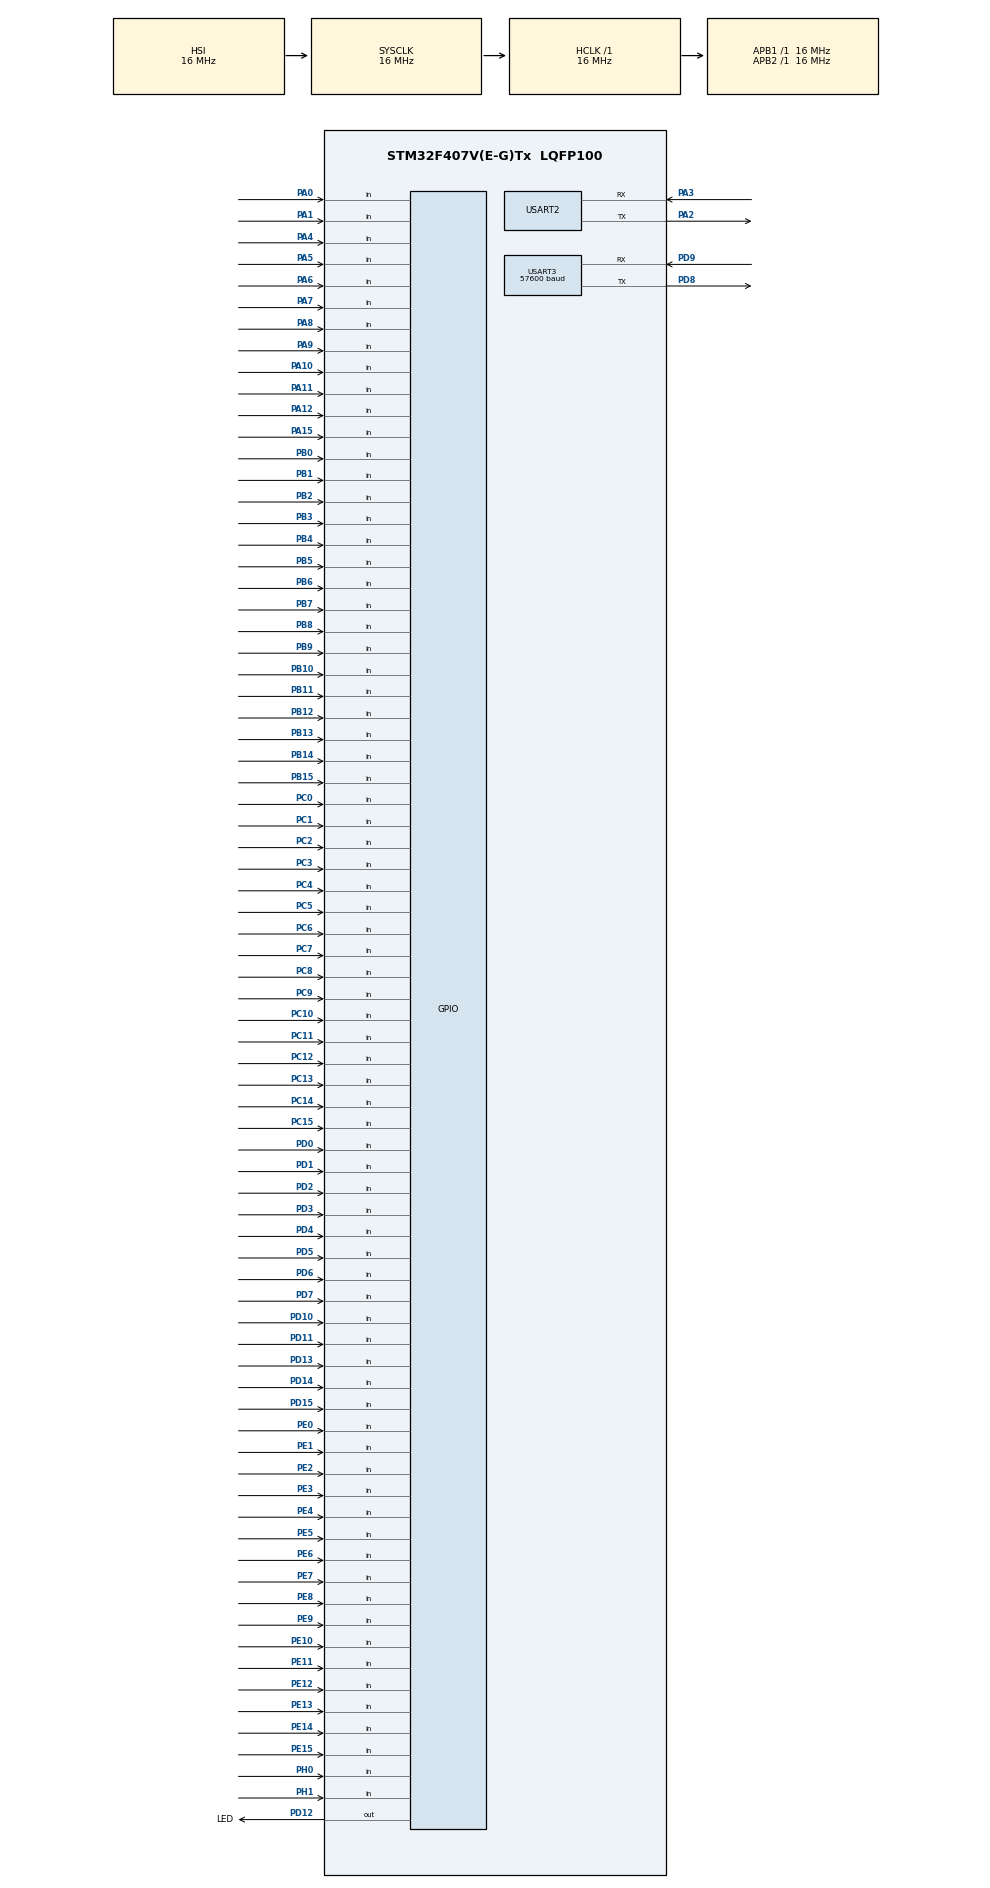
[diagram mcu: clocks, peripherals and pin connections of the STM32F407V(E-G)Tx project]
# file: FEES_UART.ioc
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FREERTOS.Tasks01=defaultTask,24,128,StartDefaultTask,Default,NULL,Dynamic,NULL,NULL
Mcu.Family=STM32F4
Mcu.Name=STM32F407V(E-G)Tx
Mcu.Package=LQFP100
NVIC.PriorityGroup=NVIC_PRIORITYGROUP_4
NVIC.TIM6_DAC_IRQn=true\:0\:0\:false\:false\:true\:false\:false\:true
NVIC.TimeBase=TIM6_DAC_IRQn
NVIC.TimeBaseIP=TIM6
NVIC.USART3_IRQn=true\:0\:0\:false\:false\:true\:true\:true\:true
PA0-WKUP.Signal=GPIO_Input
PA1.Signal=GPIO_Input
PA10.Signal=GPIO_Input
PA11.Signal=GPIO_Input
PA12.Signal=GPIO_Input
PA13.Mode=Serial_Wire
PA13.Signal=SYS_JTMS-SWDIO
PA14.Mode=Serial_Wire
PA14.Signal=SYS_JTCK-SWCLK
PA15.Signal=GPIO_Input
PA2.Mode=Asynchronous
PA2.Signal=USART2_TX
PA3.Mode=Asynchronous
PA3.Signal=USART2_RX
PA4.Signal=GPIO_Input
PA5.Signal=GPIO_Input
PA6.Signal=GPIO_Input
PA7.Signal=GPIO_Input
PA8.Signal=GPIO_Input
PA9.Signal=GPIO_Input
PB0.Signal=GPIO_Input
PB1.Signal=GPIO_Input
PB10.Signal=GPIO_Input
PB11.Signal=GPIO_Input
PB12.Signal=GPIO_Input
PB13.Signal=GPIO_Input
PB14.Signal=GPIO_Input
PB15.Signal=GPIO_Input
PB2.Signal=GPIO_Input
PB3.Signal=GPIO_Input
PB4.Signal=GPIO_Input
PB5.Signal=GPIO_Input
PB6.Signal=GPIO_Input
PB7.Signal=GPIO_Input
PB8.Signal=GPIO_Input
PB9.Signal=GPIO_Input
PC0.Signal=GPIO_Input
PC1.Signal=GPIO_Input
PC10.Signal=GPIO_Input
PC11.Signal=GPIO_Input
PC12.Signal=GPIO_Input
PC13-ANTI_TAMP.Signal=GPIO_Input
PC14-OSC32_IN.Signal=GPIO_Input
PC15-OSC32_OUT.Signal=GPIO_Input
PC2.Signal=GPIO_Input
PC3.Signal=GPIO_Input
PC4.Signal=GPIO_Input
PC5.Signal=GPIO_Input
PC6.Signal=GPIO_Input
PC7.Signal=GPIO_Input
PC8.Signal=GPIO_Input
PC9.Signal=GPIO_Input
PD0.Signal=GPIO_Input
PD1.Signal=GPIO_Input
PD10.Signal=GPIO_Input
PD11.Signal=GPIO_Input
PD12.GPIO_Label=LED
PD12.Signal=GPIO_Output
PD13.Signal=GPIO_Input
PD14.Signal=GPIO_Input
PD15.Signal=GPIO_Input
PD2.Signal=GPIO_Input
PD3.Signal=GPIO_Input
PD4.Signal=GPIO_Input
PD5.Signal=GPIO_Input
PD6.Signal=GPIO_Input
PD7.Signal=GPIO_Input
PD8.Mode=Asynchronous
PD8.Signal=USART3_TX
PD9.Mode=Asynchronous
PD9.Signal=USART3_RX
PE0.Signal=GPIO_Input
PE1.Signal=GPIO_Input
PE10.Signal=GPIO_Input
PE11.Signal=GPIO_Input
PE12.Signal=GPIO_Input
PE13.Signal=GPIO_Input
PE14.Signal=GPIO_Input
PE15.Signal=GPIO_Input
PE2.Signal=GPIO_Input
PE3.Signal=GPIO_Input
PE4.Signal=GPIO_Input
PE5.Signal=GPIO_Input
PE6.Signal=GPIO_Input
PE7.Signal=GPIO_Input
PE8.Signal=GPIO_Input
PE9.Signal=GPIO_Input
PH0-OSC_IN.Signal=GPIO_Input
PH1-OSC_OUT.Signal=GPIO_Input
ProjectManager.HeapSize=0x200
ProjectManager.StackSize=0x400
ProjectManager.TargetToolchain=STM32CubeIDE
RCC.AHBFreq_Value=16000000
RCC.APB1Freq_Value=16000000
RCC.APB2Freq_Value=16000000
RCC.CortexFreq_Value=16000000
RCC.HSE_VALUE=25000000
RCC.HSI_VALUE=16000000
RCC.LSE_VALUE=32768
RCC.SYSCLKFreq_VALUE=16000000
RCC.VCOOutputFreq_Value=192000000
USART2.VirtualMode=VM_ASYNC
USART3.BaudRate=57600
USART3.VirtualMode=VM_ASYNC
VP_FREERTOS_VS_CMSIS_V2.Mode=CMSIS_V2
VP_SYS_VS_tim6.Mode=TIM6
board=custom

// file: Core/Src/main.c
/* USER CODE BEGIN Header */
/**
  ******************************************************************************
  * @file           : main.c
  * @brief          : Main program body
  ******************************************************************************
  * @attention
  *
  * <h2><center>&copy; Copyright (c) 2021 STMicroelectronics.
  * All rights reserved.</center></h2>
  *
  * This software component is licensed by ST under BSD 3-Clause license,
  * the "License"; You may not use this file except in compliance with the
  * License. You may obtain a copy of the License at:
  *                        opensource.org/licenses/BSD-3-Clause
  *
  ******************************************************************************
  */
/* USER CODE END Header */
#include "main.h"
#include "cmsis_os.h"

/* USER CODE BEGIN Includes */

#include <stdio.h>
#include "TEST.h"

/* USER CODE END Includes */

UART_HandleTypeDef huart2;
UART_HandleTypeDef huart3;

/* Definitions for defaultTask */
osThreadId_t defaultTaskHandle;
const osThreadAttr_t defaultTask_attributes = {
  .name = "defaultTask",
  .priority = (osPriority_t) osPriorityNormal,
  .stack_size = 128 * 4
};

void SystemClock_Config(void);
static void MX_GPIO_Init(void);
static void MX_USART2_UART_Init(void);
static void MX_USART3_UART_Init(void);
void StartDefaultTask(void *argument);

/* USER CODE BEGIN 0 */

#define TRUE 1
#define FALSE 0

#define TESTING 0
#define TEST if(TESTING)

char newline[]="\n\r";

int FLAG=0;

int RxData=0;

char rx_buffer[2];
char tx_buffer[10];

void led_on()	{
	HAL_UART_Transmit(&huart3, (uint8_t *)  "ACCENDO!\n\r", 10, 100);
	HAL_GPIO_WritePin(GPIOD_BASE, GPIO_PIN_12, GPIO_PIN_RESET);
}
void led_off(){
	HAL_UART_Transmit(&huart3, (uint8_t *)  "SPENGO!\n\r", 9, 100);
	HAL_GPIO_WritePin(GPIOD_BASE, GPIO_PIN_12, GPIO_PIN_SET);
}

void State_Updater(){
	int a = atoi(rx_buffer);

	if(a == 00) led_off();

	if(a == 01) led_on() ;
	if(a == 02) led_off() ;

	if(a == 03) led_on() ;
	if(a == 04) led_off() ;

	if(a == 05) FLAG=1 ;
	if(a == 06) FLAG=0 ;

	if(a == 07) led_on() ;
	if(a == 8) led_off() ;

	if(a == 9) led_on() ;
	if(a == 10) led_off() ;

}

void FEES_SOS(int delay){
	  HAL_GPIO_WritePin(GPIOD_BASE, GPIO_PIN_12, GPIO_PIN_SET);

	  // S = . . .
	  HAL_GPIO_TogglePin(GPIOD_BASE, GPIO_PIN_12); 	HAL_Delay(delay); 	  	HAL_GPIO_TogglePin(GPIOD_BASE, GPIO_PIN_12);	  HAL_Delay(delay);
	  HAL_GPIO_TogglePin(GPIOD_BASE, GPIO_PIN_12); 	HAL_Delay(delay); 	  	HAL_GPIO_TogglePin(GPIOD_BASE, GPIO_PIN_12);	  HAL_Delay(delay);
	  HAL_GPIO_TogglePin(GPIOD_BASE, GPIO_PIN_12); 	HAL_Delay(delay); 	  	HAL_GPIO_TogglePin(GPIOD_BASE, GPIO_PIN_12);	  HAL_Delay(delay);
	  // O = - - -
	  HAL_GPIO_TogglePin(GPIOD_BASE, GPIO_PIN_12);	HAL_Delay(delay*2); 	HAL_GPIO_TogglePin(GPIOD_BASE, GPIO_PIN_12);	  HAL_Delay(delay*2);
	  HAL_GPIO_TogglePin(GPIOD_BASE, GPIO_PIN_12);	HAL_Delay(delay*2); 	HAL_GPIO_TogglePin(GPIOD_BASE, GPIO_PIN_12);	  HAL_Delay(delay*2);
	  HAL_GPIO_TogglePin(GPIOD_BASE, GPIO_PIN_12);	HAL_Delay(delay*2); 	HAL_GPIO_TogglePin(GPIOD_BASE, GPIO_PIN_12);	  HAL_Delay(delay*2);
	  // S = . . .
	  HAL_GPIO_TogglePin(GPIOD_BASE, GPIO_PIN_12); 	HAL_Delay(delay); 	  	HAL_GPIO_TogglePin(GPIOD_BASE, GPIO_PIN_12);	  HAL_Delay(delay);
	  HAL_GPIO_TogglePin(GPIOD_BASE, GPIO_PIN_12); 	HAL_Delay(delay); 	  	HAL_GPIO_TogglePin(GPIOD_BASE, GPIO_PIN_12);	  HAL_Delay(delay);
	  HAL_GPIO_TogglePin(GPIOD_BASE, GPIO_PIN_12); 	HAL_Delay(delay); 	  	HAL_GPIO_TogglePin(GPIOD_BASE, GPIO_PIN_12);	  HAL_Delay(delay);

	  HAL_GPIO_WritePin(GPIOD_BASE, GPIO_PIN_12, GPIO_PIN_SET);
}

/* USER CODE END 0 */

int main(void)
{

  /* MCU Configuration--------------------------------------------------------*/

  /* Reset of all peripherals, Initializes the Flash interface and the Systick. */
  HAL_Init();

  /* Configure the system clock */
  SystemClock_Config();

  /* Initialize all configured peripherals */
  MX_GPIO_Init();
  MX_USART2_UART_Init();
  MX_USART3_UART_Init();
  /* USER CODE BEGIN 2 */
  HAL_GPIO_WritePin(GPIOD_BASE, GPIO_PIN_12, GPIO_PIN_SET);

  HAL_UART_Receive_IT(&huart3, (uint8_t *) rx_buffer, 2);	// Enable the USART2 in RX mode under Interrupt  2Characters

  char StringInit[]= "== START-UP Completed == \n\r";
  HAL_UART_Transmit(&huart2, (uint8_t *)  StringInit, sizeof(StringInit)-1, 100);

  // Init Procedure
  FEES_SOS(50);

  /* USER CODE END 2 */

  /* Init scheduler */
  osKernelInitialize();

  /* Create the thread(s) */
  /* creation of defaultTask */
  defaultTaskHandle = osThreadNew(StartDefaultTask, NULL, &defaultTask_attributes);

  /* Start scheduler */
  osKernelStart();

  /* We should never get here as control is now taken by the scheduler */
  /* Infinite loop */
  while (1)
  {

  }
}

void SystemClock_Config(void)
{
  RCC_OscInitTypeDef RCC_OscInitStruct = {0};
  RCC_ClkInitTypeDef RCC_ClkInitStruct = {0};

  /** Configure the main internal regulator output voltage
  */
  __HAL_RCC_PWR_CLK_ENABLE();
  __HAL_PWR_VOLTAGESCALING_CONFIG(PWR_REGULATOR_VOLTAGE_SCALE1);
  /** Initializes the RCC Oscillators according to the specified parameters
  * in the RCC_OscInitTypeDef structure.
  */
  RCC_OscInitStruct.OscillatorType = RCC_OSCILLATORTYPE_HSI;
  RCC_OscInitStruct.HSIState = RCC_HSI_ON;
  RCC_OscInitStruct.HSICalibrationValue = RCC_HSICALIBRATION_DEFAULT;
  RCC_OscInitStruct.PLL.PLLState = RCC_PLL_NONE;
  if (HAL_RCC_OscConfig(&RCC_OscInitStruct) != HAL_OK)
  {
    Error_Handler();
  }
  /** Initializes the CPU, AHB and APB buses clocks
  */
  RCC_ClkInitStruct.ClockType = RCC_CLOCKTYPE_HCLK|RCC_CLOCKTYPE_SYSCLK
                              |RCC_CLOCKTYPE_PCLK1|RCC_CLOCKTYPE_PCLK2;
  RCC_ClkInitStruct.SYSCLKSource = RCC_SYSCLKSOURCE_HSI;
  RCC_ClkInitStruct.AHBCLKDivider = RCC_SYSCLK_DIV1;
  RCC_ClkInitStruct.APB1CLKDivider = RCC_HCLK_DIV1;
  RCC_ClkInitStruct.APB2CLKDivider = RCC_HCLK_DIV1;

  if (HAL_RCC_ClockConfig(&RCC_ClkInitStruct, FLASH_LATENCY_0) != HAL_OK)
  {
    Error_Handler();
  }
}

static void MX_USART2_UART_Init(void)
{

  huart2.Instance = USART2;
  huart2.Init.BaudRate = 115200;
  huart2.Init.WordLength = UART_WORDLENGTH_8B;
  huart2.Init.StopBits = UART_STOPBITS_1;
  huart2.Init.Parity = UART_PARITY_NONE;
  huart2.Init.Mode = UART_MODE_TX_RX;
  huart2.Init.HwFlowCtl = UART_HWCONTROL_NONE;
  huart2.Init.OverSampling = UART_OVERSAMPLING_16;
  if (HAL_UART_Init(&huart2) != HAL_OK)
  {
    Error_Handler();
  }

}

static void MX_USART3_UART_Init(void)
{

  huart3.Instance = USART3;
  huart3.Init.BaudRate = 57600;
  huart3.Init.WordLength = UART_WORDLENGTH_8B;
  huart3.Init.StopBits = UART_STOPBITS_1;
  huart3.Init.Parity = UART_PARITY_NONE;
  huart3.Init.Mode = UART_MODE_TX_RX;
  huart3.Init.HwFlowCtl = UART_HWCONTROL_NONE;
  huart3.Init.OverSampling = UART_OVERSAMPLING_16;
  if (HAL_UART_Init(&huart3) != HAL_OK)
  {
    Error_Handler();
  }

}

static void MX_GPIO_Init(void)
{
  GPIO_InitTypeDef GPIO_InitStruct = {0};

  /* GPIO Ports Clock Enable */
  __HAL_RCC_GPIOE_CLK_ENABLE();
  __HAL_RCC_GPIOC_CLK_ENABLE();
  __HAL_RCC_GPIOH_CLK_ENABLE();
  __HAL_RCC_GPIOA_CLK_ENABLE();
  __HAL_RCC_GPIOB_CLK_ENABLE();
  __HAL_RCC_GPIOD_CLK_ENABLE();

  /*Configure GPIO pin Output Level */
  HAL_GPIO_WritePin(LED_GPIO_Port, LED_Pin, GPIO_PIN_RESET);

  /*Configure GPIO pins : PE2 PE3 PE4 PE5
                           PE6 PE7 PE8 PE9
                           PE10 PE11 PE12 PE13
                           PE14 PE15 PE0 PE1 */
  GPIO_InitStruct.Pin = GPIO_PIN_2|GPIO_PIN_3|GPIO_PIN_4|GPIO_PIN_5
                          |GPIO_PIN_6|GPIO_PIN_7|GPIO_PIN_8|GPIO_PIN_9
                          |GPIO_PIN_10|GPIO_PIN_11|GPIO_PIN_12|GPIO_PIN_13
                          |GPIO_PIN_14|GPIO_PIN_15|GPIO_PIN_0|GPIO_PIN_1;
  GPIO_InitStruct.Mode = GPIO_MODE_INPUT;
  GPIO_InitStruct.Pull = GPIO_NOPULL;
  HAL_GPIO_Init(GPIOE, &GPIO_InitStruct);

  /*Configure GPIO pins : PC13 PC14 PC15 PC0
                           PC1 PC2 PC3 PC4
                           PC5 PC6 PC7 PC8
                           PC9 PC10 PC11 PC12 */
  GPIO_InitStruct.Pin = GPIO_PIN_13|GPIO_PIN_14|GPIO_PIN_15|GPIO_PIN_0
                          |GPIO_PIN_1|GPIO_PIN_2|GPIO_PIN_3|GPIO_PIN_4
                          |GPIO_PIN_5|GPIO_PIN_6|GPIO_PIN_7|GPIO_PIN_8
                          |GPIO_PIN_9|GPIO_PIN_10|GPIO_PIN_11|GPIO_PIN_12;
  GPIO_InitStruct.Mode = GPIO_MODE_INPUT;
  GPIO_InitStruct.Pull = GPIO_NOPULL;
  HAL_GPIO_Init(GPIOC, &GPIO_InitStruct);

  /*Configure GPIO pins : PH0 PH1 */
  GPIO_InitStruct.Pin = GPIO_PIN_0|GPIO_PIN_1;
  GPIO_InitStruct.Mode = GPIO_MODE_INPUT;
  GPIO_InitStruct.Pull = GPIO_NOPULL;
  HAL_GPIO_Init(GPIOH, &GPIO_InitStruct);

  /*Configure GPIO pins : PA0 PA1 PA4 PA5
                           PA6 PA7 PA8 PA9
                           PA10 PA11 PA12 PA15 */
  GPIO_InitStruct.Pin = GPIO_PIN_0|GPIO_PIN_1|GPIO_PIN_4|GPIO_PIN_5
                          |GPIO_PIN_6|GPIO_PIN_7|GPIO_PIN_8|GPIO_PIN_9
                          |GPIO_PIN_10|GPIO_PIN_11|GPIO_PIN_12|GPIO_PIN_15;
  GPIO_InitStruct.Mode = GPIO_MODE_INPUT;
  GPIO_InitStruct.Pull = GPIO_NOPULL;
  HAL_GPIO_Init(GPIOA, &GPIO_InitStruct);

  /*Configure GPIO pins : PB0 PB1 PB2 PB10
                           PB11 PB12 PB13 PB14
                           PB15 PB3 PB4 PB5
                           PB6 PB7 PB8 PB9 */
  GPIO_InitStruct.Pin = GPIO_PIN_0|GPIO_PIN_1|GPIO_PIN_2|GPIO_PIN_10
                          |GPIO_PIN_11|GPIO_PIN_12|GPIO_PIN_13|GPIO_PIN_14
                          |GPIO_PIN_15|GPIO_PIN_3|GPIO_PIN_4|GPIO_PIN_5
                          |GPIO_PIN_6|GPIO_PIN_7|GPIO_PIN_8|GPIO_PIN_9;
  GPIO_InitStruct.Mode = GPIO_MODE_INPUT;
  GPIO_InitStruct.Pull = GPIO_NOPULL;
  HAL_GPIO_Init(GPIOB, &GPIO_InitStruct);

  /*Configure GPIO pins : PD10 PD11 PD13 PD14
                           PD15 PD0 PD1 PD2
                           PD3 PD4 PD5 PD6
                           PD7 */
  GPIO_InitStruct.Pin = GPIO_PIN_10|GPIO_PIN_11|GPIO_PIN_13|GPIO_PIN_14
                          |GPIO_PIN_15|GPIO_PIN_0|GPIO_PIN_1|GPIO_PIN_2
                          |GPIO_PIN_3|GPIO_PIN_4|GPIO_PIN_5|GPIO_PIN_6
                          |GPIO_PIN_7;
  GPIO_InitStruct.Mode = GPIO_MODE_INPUT;
  GPIO_InitStruct.Pull = GPIO_NOPULL;
  HAL_GPIO_Init(GPIOD, &GPIO_InitStruct);

  /*Configure GPIO pin : LED_Pin */
  GPIO_InitStruct.Pin = LED_Pin;
  GPIO_InitStruct.Mode = GPIO_MODE_OUTPUT_PP;
  GPIO_InitStruct.Pull = GPIO_NOPULL;
  GPIO_InitStruct.Speed = GPIO_SPEED_FREQ_LOW;
  HAL_GPIO_Init(LED_GPIO_Port, &GPIO_InitStruct);

}

/* USER CODE BEGIN 4 */

// RX char from USART2 in Interrupt mode
void HAL_UART_RxCpltCallback(UART_HandleTypeDef *huart)
{
	  RxData=TRUE;
	  HAL_UART_Transmit(&huart3,  (uint8_t *) newline, sizeof(newline), 100);
	  HAL_UART_Transmit(&huart3,  (uint8_t *) " - I RECEIVED : ", 16 , 100);
	  HAL_UART_Transmit(&huart3,  (uint8_t *) rx_buffer, sizeof(rx_buffer), 100);
	  HAL_UART_Transmit(&huart3,  (uint8_t *) newline, sizeof(newline), 100);

	 // if(huart2.Instance->RDR != 13) huart2.Instance->RDR = 13;

  // Restart USART in Rx in Interrupt mode
  HAL_UART_Receive_IT(&huart3, (uint8_t *)  rx_buffer, sizeof(rx_buffer));

  State_Updater();
}

/* USER CODE END 4 */

void StartDefaultTask(void *argument)
{
  /* USER CODE BEGIN 5 */
  /* Infinite loop */
  for(;;)
  {
    osDelay(250);
    char StandardString[]= "I'm ALIVE! \r\n";
    char StringExtra[]= "============= \r\n";

    if(FLAG){
    		HAL_UART_Transmit(&huart3,  (uint8_t *) StandardString, sizeof(StandardString)-1 , 100);
    		HAL_UART_Transmit(&huart3,  (uint8_t *) StringExtra, sizeof(StringExtra)-1 , 100);
    	  }

    TEST Testiamo();
    TEST osDelay(1000);

    }
  /* USER CODE END 5 */
}

void HAL_TIM_PeriodElapsedCallback(TIM_HandleTypeDef *htim)
{
  if (htim->Instance == TIM6) {
    HAL_IncTick();
  }
}

void Error_Handler(void)
{
}

/************************ (C) COPYRIGHT STMicroelectronics *****END OF FILE****/
